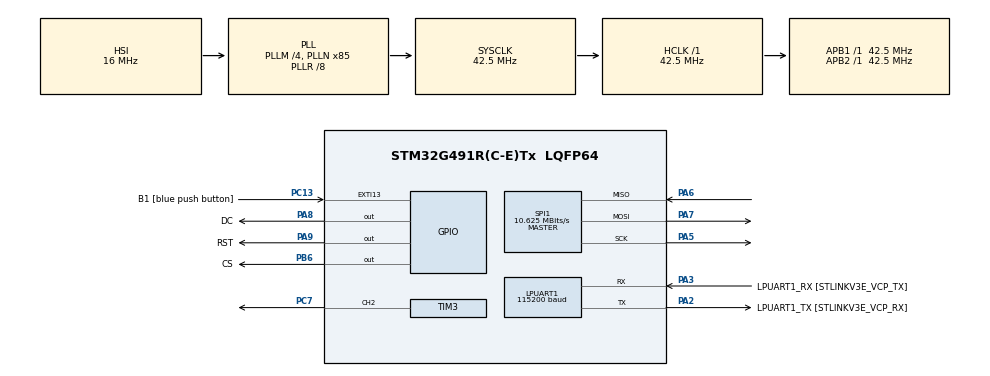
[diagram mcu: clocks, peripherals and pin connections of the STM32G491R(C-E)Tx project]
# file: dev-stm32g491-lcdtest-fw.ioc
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LPUART1.BaudRate=115200
LPUART1.WordLength=UART_WORDLENGTH_8B
Mcu.Family=STM32G4
Mcu.Name=STM32G491R(C-E)Tx
Mcu.Package=LQFP64
NVIC.EXTI15_10_IRQn=true\:0\:0\:false\:false\:true\:true\:true\:true
NVIC.PriorityGroup=NVIC_PRIORITYGROUP_4
PA13.GPIO_Label=T_SWDIO
PA13.Mode=Serial_Wire
PA13.Signal=SYS_JTMS-SWDIO
PA14.GPIO_Label=T_SWCLK
PA14.Mode=Serial_Wire
PA14.Signal=SYS_JTCK-SWCLK
PA2.GPIO_Label=LPUART1_TX [STLINKV3E_VCP_RX]
PA2.Mode=Asynchronous
PA2.Signal=LPUART1_TX
PA3.GPIO_Label=LPUART1_RX [STLINKV3E_VCP_TX]
PA3.Mode=Asynchronous
PA3.Signal=LPUART1_RX
PA5.Mode=Full_Duplex_Master
PA5.Signal=SPI1_SCK
PA6.Mode=Full_Duplex_Master
PA6.Signal=SPI1_MISO
PA7.Mode=Full_Duplex_Master
PA7.Signal=SPI1_MOSI
PA8.GPIO_Label=DC
PA8.Signal=GPIO_Output
PA9.GPIO_Label=RST
PA9.Signal=GPIO_Output
PB3.GPIO_Label=T_SWO
PB3.Signal=SYS_JTDO-SWO
PB6.GPIO_Label=CS
PB6.Signal=GPIO_Output
PC13.GPIO_Label=B1 [blue push button]
PC13.Signal=GPXTI13
PC14-OSC32_IN.Mode=LSE-External-Oscillator
PC14-OSC32_IN.Signal=RCC_OSC32_IN
PC15-OSC32_OUT.Mode=LSE-External-Oscillator
PC15-OSC32_OUT.Signal=RCC_OSC32_OUT
PC7.Signal=S_TIM3_CH2
PF0-OSC_IN.Mode=HSE-External-Oscillator
PF0-OSC_IN.Signal=RCC_OSC_IN
PF1-OSC_OUT.Mode=HSE-External-Oscillator
PF1-OSC_OUT.Signal=RCC_OSC_OUT
ProjectManager.HeapSize=0x200
ProjectManager.StackSize=0x400
ProjectManager.TargetToolchain=STM32CubeIDE
RCC.ADC12Freq_Value=42500000
RCC.ADC345Freq_Value=42500000
RCC.AHBFreq_Value=42500000
RCC.APB1Freq_Value=42500000
RCC.APB1TimFreq_Value=42500000
RCC.APB2Freq_Value=42500000
RCC.APB2TimFreq_Value=42500000
RCC.CortexFreq_Value=42500000
RCC.EXTERNAL_CLOCK_VALUE=12288000
RCC.HCLKFreq_Value=42500000
RCC.HSE_VALUE=24000000
RCC.HSI48_VALUE=48000000
RCC.HSI_VALUE=16000000
RCC.PLLM=RCC_PLLM_DIV4
RCC.PLLN=85
RCC.PLLR=RCC_PLLR_DIV8
RCC.RTCClockSelection=RCC_RTCCLKSOURCE_LSE
RCC.SYSCLKFreq_VALUE=42500000
RCC.SYSCLKSource=RCC_SYSCLKSOURCE_PLLCLK
RCC.USBFreq_Value=48000000
RCC.VCOOutputFreq_Value=340000000
SH.S_TIM3_CH2.0=TIM3_CH2,PWM Generation2 CH2
SPI1.BaudRatePrescaler=SPI_BAUDRATEPRESCALER_4
SPI1.CalculateBaudRate=10.625 MBits/s
SPI1.DataSize=SPI_DATASIZE_8BIT
SPI1.Direction=SPI_DIRECTION_2LINES
SPI1.Mode=SPI_MODE_MASTER
SPI1.VirtualType=VM_MASTER
TIM3.AutoReloadPreload=TIM_AUTORELOAD_PRELOAD_ENABLE
TIM3.Channel-PWM\ Generation2\ CH2=TIM_CHANNEL_2
TIM3.PeriodNoDither=1000-1
TIM3.Prescaler=300-1
VP_SYS_VS_DBSignals.Mode=DisableDeadBatterySignals
board=NUCLEO-G491RE

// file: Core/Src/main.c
/* USER CODE BEGIN Header */
/**
 ******************************************************************************
 * @file           : main.c
 * @brief          : Main program body
 ******************************************************************************
 * @attention
 *
 * Copyright (c) 2024 STMicroelectronics.
 * All rights reserved.
 *
 * This software is licensed under terms that can be found in the LICENSE file
 * in the root directory of this software component.
 * If no LICENSE file comes with this software, it is provided AS-IS.
 *
 ******************************************************************************
 */
/* USER CODE END Header */
#include "main.h"

/* USER CODE BEGIN Includes */

/* Includes ------------------------------------------------------------------*/
#include "main.h"

/* Private includes ----------------------------------------------------------*/
/* USER CODE BEGIN Includes */
#include "../../lcd_driver/config/debug.h"
#include "../../lcd_driver/config/dev_config.h"
#include "../../lcd_driver/gui_dev/GUI_Paint.h"
#include "../../lcd_driver/fonts/fonts.h"
#include "../../lcd_driver/image/image.h"
#include "../../lcd_driver/example/LCD_Test.h"
/* USER CODE END Includes */

UART_HandleTypeDef hlpuart1;

SPI_HandleTypeDef hspi1;

TIM_HandleTypeDef htim3;

void SystemClock_Config(void);
static void MX_GPIO_Init(void);
static void MX_LPUART1_UART_Init(void);
static void MX_TIM3_Init(void);
static void MX_SPI1_Init(void);

int main(void)
{

  /* MCU Configuration--------------------------------------------------------*/

  /* Reset of all peripherals, Initializes the Flash interface and the Systick. */
  HAL_Init();

  /* Configure the system clock */
  SystemClock_Config();

  /* Initialize all configured peripherals */
  MX_GPIO_Init();
  MX_LPUART1_UART_Init();
  MX_TIM3_Init();
  MX_SPI1_Init();

  /* Infinite loop */
  /* USER CODE BEGIN WHILE */
  LCD_1in9_test();
	while (1) {
    /* USER CODE END WHILE */

	}
}

void SystemClock_Config(void)
{
  RCC_OscInitTypeDef RCC_OscInitStruct = {0};
  RCC_ClkInitTypeDef RCC_ClkInitStruct = {0};

  /** Configure the main internal regulator output voltage
  */
  HAL_PWREx_ControlVoltageScaling(PWR_REGULATOR_VOLTAGE_SCALE1);

  /** Initializes the RCC Oscillators according to the specified parameters
  * in the RCC_OscInitTypeDef structure.
  */
  RCC_OscInitStruct.OscillatorType = RCC_OSCILLATORTYPE_HSI;
  RCC_OscInitStruct.HSIState = RCC_HSI_ON;
  RCC_OscInitStruct.HSICalibrationValue = RCC_HSICALIBRATION_DEFAULT;
  RCC_OscInitStruct.PLL.PLLState = RCC_PLL_ON;
  RCC_OscInitStruct.PLL.PLLSource = RCC_PLLSOURCE_HSI;
  RCC_OscInitStruct.PLL.PLLM = RCC_PLLM_DIV4;
  RCC_OscInitStruct.PLL.PLLN = 85;
  RCC_OscInitStruct.PLL.PLLP = RCC_PLLP_DIV2;
  RCC_OscInitStruct.PLL.PLLQ = RCC_PLLQ_DIV2;
  RCC_OscInitStruct.PLL.PLLR = RCC_PLLR_DIV8;
  if (HAL_RCC_OscConfig(&RCC_OscInitStruct) != HAL_OK)
  {
    Error_Handler();
  }

  /** Initializes the CPU, AHB and APB buses clocks
  */
  RCC_ClkInitStruct.ClockType = RCC_CLOCKTYPE_HCLK|RCC_CLOCKTYPE_SYSCLK
                              |RCC_CLOCKTYPE_PCLK1|RCC_CLOCKTYPE_PCLK2;
  RCC_ClkInitStruct.SYSCLKSource = RCC_SYSCLKSOURCE_PLLCLK;
  RCC_ClkInitStruct.AHBCLKDivider = RCC_SYSCLK_DIV1;
  RCC_ClkInitStruct.APB1CLKDivider = RCC_HCLK_DIV1;
  RCC_ClkInitStruct.APB2CLKDivider = RCC_HCLK_DIV1;

  if (HAL_RCC_ClockConfig(&RCC_ClkInitStruct, FLASH_LATENCY_1) != HAL_OK)
  {
    Error_Handler();
  }
}

static void MX_LPUART1_UART_Init(void)
{

  hlpuart1.Instance = LPUART1;
  hlpuart1.Init.BaudRate = 115200;
  hlpuart1.Init.WordLength = UART_WORDLENGTH_8B;
  hlpuart1.Init.StopBits = UART_STOPBITS_1;
  hlpuart1.Init.Parity = UART_PARITY_NONE;
  hlpuart1.Init.Mode = UART_MODE_TX_RX;
  hlpuart1.Init.HwFlowCtl = UART_HWCONTROL_NONE;
  hlpuart1.Init.OneBitSampling = UART_ONE_BIT_SAMPLE_DISABLE;
  hlpuart1.Init.ClockPrescaler = UART_PRESCALER_DIV1;
  hlpuart1.AdvancedInit.AdvFeatureInit = UART_ADVFEATURE_NO_INIT;
  if (HAL_UART_Init(&hlpuart1) != HAL_OK)
  {
    Error_Handler();
  }
  if (HAL_UARTEx_SetTxFifoThreshold(&hlpuart1, UART_TXFIFO_THRESHOLD_1_8) != HAL_OK)
  {
    Error_Handler();
  }
  if (HAL_UARTEx_SetRxFifoThreshold(&hlpuart1, UART_RXFIFO_THRESHOLD_1_8) != HAL_OK)
  {
    Error_Handler();
  }
  if (HAL_UARTEx_DisableFifoMode(&hlpuart1) != HAL_OK)
  {
    Error_Handler();
  }

}

static void MX_SPI1_Init(void)
{

  /* SPI1 parameter configuration*/
  hspi1.Instance = SPI1;
  hspi1.Init.Mode = SPI_MODE_MASTER;
  hspi1.Init.Direction = SPI_DIRECTION_2LINES;
  hspi1.Init.DataSize = SPI_DATASIZE_8BIT;
  hspi1.Init.CLKPolarity = SPI_POLARITY_LOW;
  hspi1.Init.CLKPhase = SPI_PHASE_1EDGE;
  hspi1.Init.NSS = SPI_NSS_SOFT;
  hspi1.Init.BaudRatePrescaler = SPI_BAUDRATEPRESCALER_4;
  hspi1.Init.FirstBit = SPI_FIRSTBIT_MSB;
  hspi1.Init.TIMode = SPI_TIMODE_DISABLE;
  hspi1.Init.CRCCalculation = SPI_CRCCALCULATION_DISABLE;
  hspi1.Init.CRCPolynomial = 7;
  hspi1.Init.CRCLength = SPI_CRC_LENGTH_DATASIZE;
  hspi1.Init.NSSPMode = SPI_NSS_PULSE_ENABLE;
  if (HAL_SPI_Init(&hspi1) != HAL_OK)
  {
    Error_Handler();
  }

}

static void MX_TIM3_Init(void)
{

  TIM_MasterConfigTypeDef sMasterConfig = {0};
  TIM_OC_InitTypeDef sConfigOC = {0};

  htim3.Instance = TIM3;
  htim3.Init.Prescaler = 300-1;
  htim3.Init.CounterMode = TIM_COUNTERMODE_UP;
  htim3.Init.Period = 999;
  htim3.Init.ClockDivision = TIM_CLOCKDIVISION_DIV1;
  htim3.Init.AutoReloadPreload = TIM_AUTORELOAD_PRELOAD_ENABLE;
  if (HAL_TIM_PWM_Init(&htim3) != HAL_OK)
  {
    Error_Handler();
  }
  sMasterConfig.MasterOutputTrigger = TIM_TRGO_RESET;
  sMasterConfig.MasterSlaveMode = TIM_MASTERSLAVEMODE_DISABLE;
  if (HAL_TIMEx_MasterConfigSynchronization(&htim3, &sMasterConfig) != HAL_OK)
  {
    Error_Handler();
  }
  sConfigOC.OCMode = TIM_OCMODE_PWM1;
  sConfigOC.Pulse = 0;
  sConfigOC.OCPolarity = TIM_OCPOLARITY_HIGH;
  sConfigOC.OCFastMode = TIM_OCFAST_DISABLE;
  if (HAL_TIM_PWM_ConfigChannel(&htim3, &sConfigOC, TIM_CHANNEL_2) != HAL_OK)
  {
    Error_Handler();
  }
  HAL_TIM_MspPostInit(&htim3);

}

static void MX_GPIO_Init(void)
{
  GPIO_InitTypeDef GPIO_InitStruct = {0};

  /* GPIO Ports Clock Enable */
  __HAL_RCC_GPIOC_CLK_ENABLE();
  __HAL_RCC_GPIOF_CLK_ENABLE();
  __HAL_RCC_GPIOA_CLK_ENABLE();
  __HAL_RCC_GPIOB_CLK_ENABLE();

  /*Configure GPIO pin Output Level */
  HAL_GPIO_WritePin(GPIOA, DC_Pin|RST_Pin, GPIO_PIN_RESET);

  /*Configure GPIO pin Output Level */
  HAL_GPIO_WritePin(CS_GPIO_Port, CS_Pin, GPIO_PIN_RESET);

  /*Configure GPIO pin : B1_Pin */
  GPIO_InitStruct.Pin = B1_Pin;
  GPIO_InitStruct.Mode = GPIO_MODE_IT_RISING;
  GPIO_InitStruct.Pull = GPIO_NOPULL;
  HAL_GPIO_Init(B1_GPIO_Port, &GPIO_InitStruct);

  /*Configure GPIO pins : DC_Pin RST_Pin */
  GPIO_InitStruct.Pin = DC_Pin|RST_Pin;
  GPIO_InitStruct.Mode = GPIO_MODE_OUTPUT_PP;
  GPIO_InitStruct.Pull = GPIO_NOPULL;
  GPIO_InitStruct.Speed = GPIO_SPEED_FREQ_LOW;
  HAL_GPIO_Init(GPIOA, &GPIO_InitStruct);

  /*Configure GPIO pin : CS_Pin */
  GPIO_InitStruct.Pin = CS_Pin;
  GPIO_InitStruct.Mode = GPIO_MODE_OUTPUT_PP;
  GPIO_InitStruct.Pull = GPIO_NOPULL;
  GPIO_InitStruct.Speed = GPIO_SPEED_FREQ_LOW;
  HAL_GPIO_Init(CS_GPIO_Port, &GPIO_InitStruct);

  /* EXTI interrupt init*/
  HAL_NVIC_SetPriority(EXTI15_10_IRQn, 0, 0);
  HAL_NVIC_EnableIRQ(EXTI15_10_IRQn);

}

void Error_Handler(void)
{
	__disable_irq();
	while (1) {
	}
}
